# ADC_SAFETY_ADC_SAFETY_502CB400h register map
Vendor: Texas Instruments
Peripheral module from a debugger description file (folder AM261x).
Registers are 16-bit, read-only, reset 0x0 unless marked. A register's access mark holds for its fields unless they carry their own. Offsets are as the file gives them; lines under a group give offsets from that group; [hi:lo] are bit positions; {n}, {i} and the like mark numbered series; 'fields as' and 'values as' point back to an identical list; <NAME> marks a mode.

## adc_safety
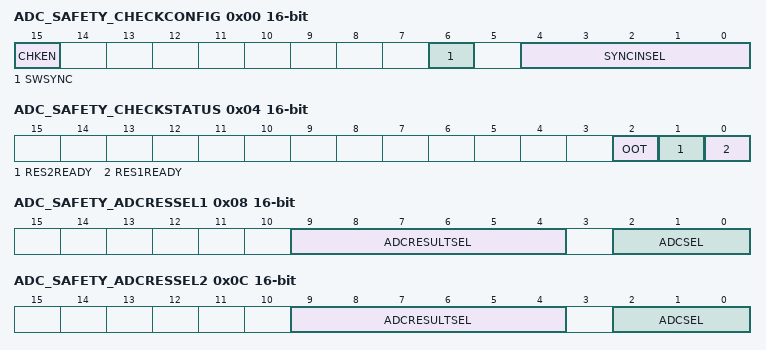
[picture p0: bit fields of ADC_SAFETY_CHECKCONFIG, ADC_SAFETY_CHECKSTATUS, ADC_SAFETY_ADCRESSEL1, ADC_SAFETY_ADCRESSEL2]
0x00 ADC_SAFETY_CHECKCONFIG access not given — ADC Check Configuration Register.
  [15] CHKEN rw — Result Safe Check Module enable
  [6] SWSYNC — Result Safe Check SW Force Sync. (access R/W1TS)
  [4:0] SYNCINSEL ro — Result Safe Check Sync. In sel Needed?
0x04 ADC_SAFETY_CHECKSTATUS — ADC Check Status Register.
  [2] OOT — Set when the difference between CHECKRESULT1 and CHECKRESULT2 is greater than TOLERANCE after both results have arrived. When set, further results will not be captured into the safety checker module CHECKRESULT1 or CHECKRESULT2 registers and further OOT or OVF events can't be generated. Cleared when the associated OOTx flag for all CPUs are either cleared [via the OOTFLGCLR.OOTx bit] or disabled to all ISR and events [via the CHECKINTSEL3.OOTx, CHECKEVT1SEL3.OOTx, CHECKEVT2SEL3.OOTx, CHECKEVT3SEL3.OOTx, and CHECKEVT4SEL3.OOTx registers]
  [1] RES2READY — Result Safe Check Result 2 arrived. Cleared automatically when both results have arrived and the comparison occurs. Can also be cleared by issuing a software sync to the tile via the CHECKCONFIG.SWSYNC field.
  [0] RES1READY — Result Safe Check Result 1 arrived. Cleared automatically when both results have arrived and the comparison occurs. Can also be cleared by issuing a software sync to the tile via the CHECKCONFIG.SWSYNC field.
0x08 ADC_SAFETY_ADCRESSEL1 rw — ADC Check 1 Select Register.
  [9:4] ADCRESULTSEL — ADC Result Safety Checker Result Select 1 0 = ADCRESULT0 1 = ADCRESULT1 2= ADCRESULT2 3 = ADCRESULT3 4 = ADCRESULT4 5 = ADCRESULT5 6 = ADCRESULT6 7 = ADCRESULT7 8 = ADCRESULT8 9 = ADCRESULT9 10 = ADCRESULT10 11 = ADCRESULT11 12 = ADCRESULT12 13 = ADCRESULT13 14 = ADCRESULT14 15 = ADCRESULT15 16 = RESERVED 17 = RESERVED 18 = RESERVED 19 = RESERVED 20 = RESERVED 21 = RESERVED 22 = RESERVED 23 = RESERVED 24 = RESERVED 25 = RESERVED 26 = RESERVED 27 = RESERVED 28 = RESERVED 29 = RESERVED 30 = RESERVED 31 = RESERVED 32 = ADCPPBRESULT1 33 = ADCPPBRESULT2 34 = ADCPPBRESULT3 35 = ADCPPBRESULT4 36 = ADCPPBSUM1 37 = ADCPPBSUM2 38 = ADCPPBSUM3 39 = ADCPPBSUM4 ... 40 - 61 = Reserved
  [2:0] ADCSEL — ADC Result Safety Checker ADC Select 1 0 = ADC-0 1 = ADC-1 2 = ADC-2 3 = ADC-3 4 = ADC-45 - 7 = Reserved
0x0C ADC_SAFETY_ADCRESSEL2 rw — ADC Check 2 Select Register.
  [9:4] ADCRESULTSEL — ADC Result Safety Checker Result Select 2 0 = ADCRESULT0 1 = ADCRESULT1 2= ADCRESULT2 3 = ADCRESULT3 4 = ADCRESULT4 5 = ADCRESULT5 6 = ADCRESULT6 7 = ADCRESULT7 8 = ADCRESULT8 9 = ADCRESULT9 10 = ADCRESULT10 11 = ADCRESULT11 12 = ADCRESULT12 13 = ADCRESULT13 14 = ADCRESULT14 15 = ADCRESULT15 16 = RESERVED 17 = RESERVED 18 = RESERVED 19 = RESERVED 20 = RESERVED 21 = RESERVED 22 = RESERVED 23 = RESERVED 24 = RESERVED 25 = RESERVED 26 = RESERVED 27 = RESERVED 28 = RESERVED 29 = RESERVED 30 = RESERVED 31 = RESERVED 32 = ADCPPBRESULT1 33 = ADCPPBRESULT2 34 = ADCPPBRESULT3 35 = ADCPPBRESULT4 36 = ADCPPBSUM1 37 = ADCPPBSUM2 38 = ADCPPBSUM3 39 = ADCPPBSUM4 ... 40 - 61 = Reserved
  [2:0] ADCSEL — ADC Result Safety Checker ADC Select 2 0 = ADC-0 1 = ADC-1 2 = ADC-2 3 = ADC-3 4 = ADC-4 5 - 7 = Reserved
0x10 ADC_SAFETY_TOLERANCE 32-bit rw — ADC Check Tolerance Register.
  [23:0] TOLERANCE — Tolerance for the difference between CHECKRESULT1 and CHECKRESULT2. If the difference is greater than [but not equal to] the tolerance, an out-of-tolerance event will be generated, indicated the compared ADC results are not within expected tolerance of each other.
0x18 ADC_SAFETY_CHECKRESULT1 32-bit — ADC Check Captured Result 1 .
  [23:0] RESULT — ADC Result Safety Checker Captured Result Result that was captured In the case that multiple results arrive for one selected result before one result arrives for the other result for comparison, the RES1OVF flag in CHECKSTATUS will be set. This does not prevent CHECKRESULT1 from updating to the latest result.
0x1C ADC_SAFETY_CHECKRESULT2 32-bit — ADC Check Captured Result 2 .
  [23:0] RESULT — ADC Result Safety Checker Captured Result Result that was captured In the case that multiple results arrive for one selected result before one result arrives for the other result for comparison, the RES2OVF flag in CHECKSTATUS will be set. This does not prevent CHECKRESULT2 from updating to the latest result.
